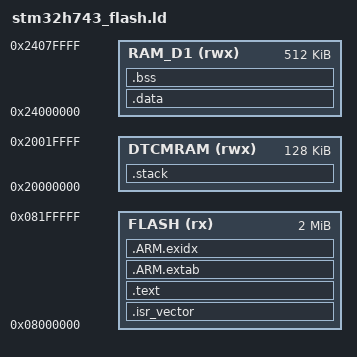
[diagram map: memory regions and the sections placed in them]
MEMORY
{
  FLASH (rx)  : ORIGIN = 0x08000000, LENGTH = 2048K
  DTCMRAM (rwx) : ORIGIN = 0x20000000, LENGTH = 128K
  RAM_D1 (rwx)  : ORIGIN = 0x24000000, LENGTH = 512K
}

ENTRY(Reset_Handler)

SECTIONS
{
  .isr_vector : { KEEP(*(.isr_vector)) } > FLASH
  .text :
  {
    *(.text*)
    *(.rodata*)
    KEEP(*(.init))
    KEEP(*(.fini))
    . = ALIGN(4);
  } > FLASH

  .ARM.extab :
  {
    *(.ARM.extab* .gnu.linkonce.armextab.*)
    . = ALIGN(4);
  } > FLASH

  .ARM.exidx :
  {
    *(.ARM.exidx* .gnu.linkonce.armexidx.*)
    . = ALIGN(4);
    _etext = .;
  } > FLASH

  .data : AT(_etext)
  {
    . = ALIGN(4);
    _sdata = .;
    *(.data*)
    . = ALIGN(4);
    _edata = .;
  } > RAM_D1

  .bss :
  {
    . = ALIGN(4);
    _sbss = .;
    *(.bss*)
    *(COMMON)
    . = ALIGN(4);
    _ebss = .;
    _end = .;
  } > RAM_D1

  .stack (NOLOAD):
  {
    . = ALIGN(8);
    . = . + 0x8000;
    . = ALIGN(8);
    _estack = .;
  } > DTCMRAM
}
